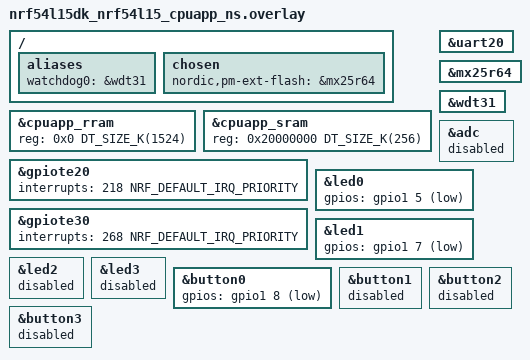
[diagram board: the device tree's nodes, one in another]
/*
 * Copyright (c) 2024 Nordic Semiconductor ASA
 *
 * SPDX-License-Identifier: LicenseRef-Nordic-5-Clause
 */

/ {
	aliases {
		// Use watchdog wdt31 as the application watchdog
		watchdog0 = &wdt31;
	};

	chosen {
		nordic,pm-ext-flash = &mx25r64;
	};
};

// restore full RRAM and SRAM space - by default some parts are dedicated to FLRP
&cpuapp_rram {
	reg = <0x0 DT_SIZE_K(1524)>;
};

&cpuapp_sram {
	reg = <0x20000000 DT_SIZE_K(256)>;
	ranges = <0x0 0x20000000  0x40000>;
};

// TODO: re-enable HWFC once it's fixed
&uart20 {
	/delete-property/ hw-flow-control;
};

&mx25r64 {
	status = "okay";
};

&wdt31 {
	status = "okay";
};

// Change IRQ ids to handle button interrupts.

// The default values for nRF54L15 are 219 and 269,
// but with TF-M they are reserved for the secure domain
// (218 and 268 are reserved for the non-secure domain).
&gpiote20 {
	interrupts = <218 NRF_DEFAULT_IRQ_PRIORITY>;
};

&gpiote30 {
	interrupts = <268 NRF_DEFAULT_IRQ_PRIORITY>;
};


&adc {
	status = "disabled";
};

&led0 {
	gpios = <&gpio1 5 GPIO_ACTIVE_LOW>;
};
&led1 {
	gpios = <&gpio1 7 GPIO_ACTIVE_LOW>;
};
/* Disable led2 and led3 since they are now used as relay control pins */
&led2 {
	status = "disabled";
};

&led3 {
	status = "disabled";
};

&button0 {
	gpios = <&gpio1 8 GPIO_ACTIVE_LOW>;
	status = "okay";
};


&button1 {
	status = "disabled";
};

&button2{
	status = "disabled";
};

&button3 {
	status = "disabled";
};
